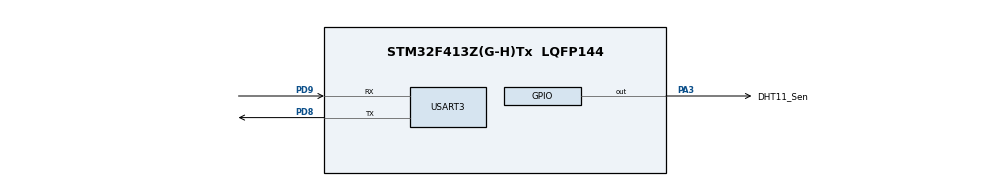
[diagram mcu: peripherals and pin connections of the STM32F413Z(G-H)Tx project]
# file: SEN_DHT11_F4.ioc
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Mcu.Family=STM32F4
Mcu.Name=STM32F413Z(G-H)Tx
Mcu.Package=LQFP144
NVIC.PriorityGroup=NVIC_PRIORITYGROUP_4
PA3.GPIO_Label=DHT11_Sen
PA3.GPIO_Speed=GPIO_SPEED_FREQ_HIGH
PA3.PinState=GPIO_PIN_SET
PA3.Signal=GPIO_Output
PD8.Mode=Asynchronous
PD8.Signal=USART3_TX
PD9.Mode=Asynchronous
PD9.Signal=USART3_RX
ProjectManager.HeapSize=0x200
ProjectManager.StackSize=0x400
ProjectManager.TargetToolchain=STM32CubeIDE
RCC.CortexFreq_Value=16000000
RCC.USBFreq_Value=96000000
RCC.VCOOutputFreq_Value=192000000
TIM6.Period=65535-1
TIM6.Prescaler=16-1
USART3.VirtualMode=VM_ASYNC
VP_TIM6_VS_ClockSourceINT.Mode=Enable_Timer
board=custom

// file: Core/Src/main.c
/* USER CODE BEGIN Header */
/**
  ******************************************************************************
  * @file           : main.c
  * @brief          : Main program body
  ******************************************************************************
  * @attention
  *
  * Copyright (c) 2023 STMicroelectronics.
  * All rights reserved.
  *
  * This software is licensed under terms that can be found in the LICENSE file
  * in the root directory of this software component.
  * If no LICENSE file comes with this software, it is provided AS-IS.
  *
  ******************************************************************************
  */
/* USER CODE END Header */
#include "main.h"

/* USER CODE BEGIN Includes */
#include "stdio.h"
#include "string.h"
/* USER CODE END Includes */

TIM_HandleTypeDef htim6;

UART_HandleTypeDef huart3;

void SystemClock_Config(void);
static void MX_GPIO_Init(void);
static void MX_USART3_UART_Init(void);
static void MX_TIM6_Init(void);

/* USER CODE BEGIN 0 */

/************************* Start delay function *************************/
void delay(uint16_t length) {
	/* TIM6 timer settings in STM32CubeMX are
	 * - HCLK: 16 MHz.
	 * - APB1: 16 MHz.
	 * - TIM6 Pre-scalar: 16-1 thus APB1 is scaled to 1 MHz
	 * - TIM6 Counter period: 65535-1. Thus, the maximum counter period is 65.535 ms.
	 *
	 * The maximum signal length of the DHT11 protocol in all phases (initialization, response,
	 * and data transmission) is 18 ms. Thus, a timer length of 65.535 ms is more than enough.
	 * The counter is increasing.
	 */
	__HAL_TIM_SET_COUNTER(&htim6, 0);				// Set the time to 0
	while((__HAL_TIM_GET_COUNTER(&htim6))<length);  // Increment the timer until the desired length.
}
/************************* End delay function *************************/

/************************* Start pin setup functions *************************/

#define DHT11_PORT DHT11_Sen_GPIO_Port
#define DHT11_PIN DHT11_Sen_Pin

void set_pin_output(GPIO_TypeDef *GPIOx, uint16_t GPIO_Pin) {
	GPIO_InitTypeDef GPIO_Init_Struct = {0};
	GPIO_Init_Struct.Pin = GPIO_Pin;
	GPIO_Init_Struct.Mode = GPIO_MODE_OUTPUT_PP;
	GPIO_Init_Struct.Speed = GPIO_SPEED_FREQ_HIGH; // I/O Speed is FAST
	HAL_GPIO_Init(GPIOx, &GPIO_Init_Struct);
}

void set_pin_input(GPIO_TypeDef *GPIOx, uint16_t GPIO_Pin) {
	GPIO_InitTypeDef GPIO_Init_Struct = {0};
	GPIO_Init_Struct.Pin = GPIO_Pin;
	GPIO_Init_Struct.Mode = GPIO_MODE_INPUT;
	GPIO_Init_Struct.Pull = GPIO_NOPULL;
	HAL_GPIO_Init(GPIOx, &GPIO_Init_Struct);
}

/************************* End pin setup functions *************************/

/************************* Start DHT11 functions *************************/
void DHT11_start(void){
	set_pin_output(DHT11_PORT, DHT11_PIN);
	HAL_GPIO_WritePin(DHT11_PORT, DHT11_PIN, 0);
	/*
	 * Delay of 18000 checks ok.
	 */
	delay(18000);
	HAL_GPIO_WritePin(DHT11_PORT, DHT11_PIN, 1);
	/*
	 * The DHT response interval is [20-40]us. Measured with LA5016 Logic Analyzer.
	 * Delay of 5 results in 23us
	 * Delay of 10 results in 29us increment of 6 units
	 * Delay of 15 results in 33us increment of 4 units
	 * Delay of 20 results in 39us increment of 6 units
	 * Delay of 25 results in 43us increment of 4 units
	 * Delay of 30 results in 49us increment of 6 units
	 *
	 * The linear function that best approximates the data is y = 1.5014x + 11.471.
	 * Thus for a delay of approximately 30us use 12 units
	 */
	delay(12);
	set_pin_input(DHT11_PORT, DHT11_PIN);
}

uint8_t DHT11_state(void){
	uint8_t response = 0;
	/*
	 * For a delay of approximately 40us use 19 units
	 */
	delay(19);
	if(!(HAL_GPIO_ReadPin(DHT11_PORT, DHT11_PIN))){
		/*
		 * For a delay of approximately 80us use 45 units
		 */
		delay(45);
		if(HAL_GPIO_ReadPin(DHT11_PORT, DHT11_PIN))
				response = 1;
		else 	response = -1;
	}
	// wait for pin to go low, to start data transmission
	while(HAL_GPIO_ReadPin(DHT11_PORT, DHT11_PIN));
	return response;
}

uint8_t DHT11_read(void){
	uint8_t i, j;
	for( j=0; j<8; j++){
		// wait for the pin to go high
		while(!(HAL_GPIO_ReadPin(DHT11_PORT, DHT11_PIN)));
		/*
		 * For a delay of approximately 40us use 19 units
		 */
		delay(19);
		if( !(HAL_GPIO_ReadPin(DHT11_PORT, DHT11_PIN)) )
			 i &= ~(1<<(7-j));
		else i |= (1<<(7-j));
		// wait for the pin to go low
		while((HAL_GPIO_ReadPin(DHT11_PORT, DHT11_PIN)));
	}
	return i;
}

/************************* End DHT11 functions *************************/

float temperature = 0.0;
float humidity = 0.0;
uint8_t state = 0;

/* USER CODE END 0 */

int main(void)
{
  /* USER CODE BEGIN 1 */
	char snd_buff[25] = {0};
  /* USER CODE END 1 */

  /* MCU Configuration--------------------------------------------------------*/

  /* Reset of all peripherals, Initializes the Flash interface and the Systick. */
  HAL_Init();

  /* Configure the system clock */
  SystemClock_Config();

  /* Initialize all configured peripherals */
  MX_GPIO_Init();
  MX_USART3_UART_Init();
  MX_TIM6_Init();
  /* USER CODE BEGIN 2 */
  HAL_TIM_Base_Start_IT(&htim6);
  // To give the sensor time to stabilize
  HAL_Delay(2000);
  /* USER CODE END 2 */

  /* Infinite loop */
  /* USER CODE BEGIN WHILE */
  while (1)
  {
	  DHT11_start();
	  uint8_t state = DHT11_state();
	  if( state == 1) {
		  // Humidity integer part
		  uint8_t rh_integer_part = DHT11_read();
		  // Humidity fractional part
		  uint8_t rh_fractional_part = DHT11_read();
		  // Temperature integer part
		  uint8_t temp_integer_part = DHT11_read();
		  // Temperature fractional part
		  uint8_t temp_fractional_part = DHT11_read();
		  // Checksum
		  uint8_t checksum = DHT11_read();

		  // Prepare data conversion
		  humidity    = (float) rh_integer_part + ((float)rh_fractional_part/256.0);
		  temperature = (float) temp_integer_part + ((float)temp_fractional_part/256.0);

		  // Prepare message
		  sprintf(snd_buff, "T:%.2f,H:%.2f\r\n", temperature, humidity);
		  HAL_UART_Transmit(&huart3, (uint8_t*) snd_buff, sizeof(snd_buff), 100);
	  } else {
		  sprintf(snd_buff, "E:%d\r\n", state);
		  HAL_UART_Transmit(&huart3, (uint8_t*) snd_buff, sizeof(snd_buff), 100);
	  }

	  // Sampling rate of DHT11 must not be bellow 1Hz
	  HAL_Delay(1500);
    /* USER CODE END WHILE */

  }
}

void SystemClock_Config(void)
{
  RCC_OscInitTypeDef RCC_OscInitStruct = {0};
  RCC_ClkInitTypeDef RCC_ClkInitStruct = {0};

  /** Configure the main internal regulator output voltage
  */
  __HAL_RCC_PWR_CLK_ENABLE();
  __HAL_PWR_VOLTAGESCALING_CONFIG(PWR_REGULATOR_VOLTAGE_SCALE1);

  /** Initializes the RCC Oscillators according to the specified parameters
  * in the RCC_OscInitTypeDef structure.
  */
  RCC_OscInitStruct.OscillatorType = RCC_OSCILLATORTYPE_HSI;
  RCC_OscInitStruct.HSIState = RCC_HSI_ON;
  RCC_OscInitStruct.HSICalibrationValue = RCC_HSICALIBRATION_DEFAULT;
  RCC_OscInitStruct.PLL.PLLState = RCC_PLL_NONE;
  if (HAL_RCC_OscConfig(&RCC_OscInitStruct) != HAL_OK)
  {
    Error_Handler();
  }

  /** Initializes the CPU, AHB and APB buses clocks
  */
  RCC_ClkInitStruct.ClockType = RCC_CLOCKTYPE_HCLK|RCC_CLOCKTYPE_SYSCLK
                              |RCC_CLOCKTYPE_PCLK1|RCC_CLOCKTYPE_PCLK2;
  RCC_ClkInitStruct.SYSCLKSource = RCC_SYSCLKSOURCE_HSI;
  RCC_ClkInitStruct.AHBCLKDivider = RCC_SYSCLK_DIV1;
  RCC_ClkInitStruct.APB1CLKDivider = RCC_HCLK_DIV1;
  RCC_ClkInitStruct.APB2CLKDivider = RCC_HCLK_DIV1;

  if (HAL_RCC_ClockConfig(&RCC_ClkInitStruct, FLASH_LATENCY_0) != HAL_OK)
  {
    Error_Handler();
  }
}

static void MX_TIM6_Init(void)
{

  TIM_MasterConfigTypeDef sMasterConfig = {0};

  htim6.Instance = TIM6;
  htim6.Init.Prescaler = 16-1;
  htim6.Init.CounterMode = TIM_COUNTERMODE_UP;
  htim6.Init.Period = 65535-1;
  htim6.Init.AutoReloadPreload = TIM_AUTORELOAD_PRELOAD_DISABLE;
  if (HAL_TIM_Base_Init(&htim6) != HAL_OK)
  {
    Error_Handler();
  }
  sMasterConfig.MasterOutputTrigger = TIM_TRGO_RESET;
  sMasterConfig.MasterSlaveMode = TIM_MASTERSLAVEMODE_DISABLE;
  if (HAL_TIMEx_MasterConfigSynchronization(&htim6, &sMasterConfig) != HAL_OK)
  {
    Error_Handler();
  }
  /* USER CODE BEGIN TIM6_Init 2 */
  htim6.Init.RepetitionCounter = 0;
  /* USER CODE END TIM6_Init 2 */

}

static void MX_USART3_UART_Init(void)
{

  huart3.Instance = USART3;
  huart3.Init.BaudRate = 115200;
  huart3.Init.WordLength = UART_WORDLENGTH_8B;
  huart3.Init.StopBits = UART_STOPBITS_1;
  huart3.Init.Parity = UART_PARITY_NONE;
  huart3.Init.Mode = UART_MODE_TX_RX;
  huart3.Init.HwFlowCtl = UART_HWCONTROL_NONE;
  huart3.Init.OverSampling = UART_OVERSAMPLING_16;
  if (HAL_UART_Init(&huart3) != HAL_OK)
  {
    Error_Handler();
  }

}

static void MX_GPIO_Init(void)
{
  GPIO_InitTypeDef GPIO_InitStruct = {0};

  /* GPIO Ports Clock Enable */
  __HAL_RCC_GPIOA_CLK_ENABLE();
  __HAL_RCC_GPIOD_CLK_ENABLE();

  /*Configure GPIO pin Output Level */
  HAL_GPIO_WritePin(GPIOA, GPIO_PIN_3, GPIO_PIN_SET);

  /*Configure GPIO pin : PA3 */
  GPIO_InitStruct.Pin = GPIO_PIN_3;
  GPIO_InitStruct.Mode = GPIO_MODE_OUTPUT_PP;
  GPIO_InitStruct.Pull = GPIO_NOPULL;
  GPIO_InitStruct.Speed = GPIO_SPEED_FREQ_HIGH;
  HAL_GPIO_Init(GPIOA, &GPIO_InitStruct);

}

void Error_Handler(void)
{
  __disable_irq();
  while (1)
  {
  }
}
